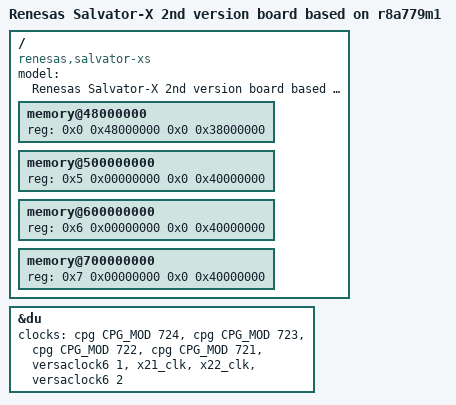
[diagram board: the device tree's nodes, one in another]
// SPDX-License-Identifier: (GPL-2.0 or MIT)
/*
 * Device Tree Source for the Salvator-X 2nd version board with R-Car H3e-2G
 *
 * Copyright (C) 2021 Glider bv
 *
 * Based on r8a77951-salvator-xs.dts
 * Copyright (C) 2015-2017 Renesas Electronics Corp.
 */

/dts-v1/;
#include "r8a779m1.dtsi"
#include "salvator-xs.dtsi"

/ {
	model = "Renesas Salvator-X 2nd version board based on r8a779m1";
	compatible = "renesas,salvator-xs", "renesas,r8a779m1",
		     "renesas,r8a7795";

	memory@48000000 {
		device_type = "memory";
		/* first 128MB is reserved for secure area. */
		reg = <0x0 0x48000000 0x0 0x38000000>;
	};

	memory@500000000 {
		device_type = "memory";
		reg = <0x5 0x00000000 0x0 0x40000000>;
	};

	memory@600000000 {
		device_type = "memory";
		reg = <0x6 0x00000000 0x0 0x40000000>;
	};

	memory@700000000 {
		device_type = "memory";
		reg = <0x7 0x00000000 0x0 0x40000000>;
	};
};

&du {
	clocks = <&cpg CPG_MOD 724>,
		 <&cpg CPG_MOD 723>,
		 <&cpg CPG_MOD 722>,
		 <&cpg CPG_MOD 721>,
		 <&versaclock6 1>,
		 <&x21_clk>,
		 <&x22_clk>,
		 <&versaclock6 2>;
	clock-names = "du.0", "du.1", "du.2", "du.3",
		      "dclkin.0", "dclkin.1", "dclkin.2", "dclkin.3";
};
